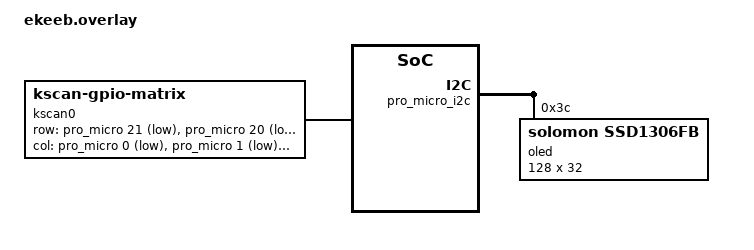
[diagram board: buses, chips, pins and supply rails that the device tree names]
/*
 * Copyright (c) 2021 The ZMK Contributors
 *
 * SPDX-License-Identifier: MIT
 */

/ {
	chosen {
		zephyr,display = &oled;
		zmk,kscan = &kscan0;
	};


	kscan0: kscan_0 {
		compatible = "zmk,kscan-gpio-matrix";

		diode-direction = "col2row";
		row-gpios
			= <&pro_micro 21  (GPIO_ACTIVE_LOW | GPIO_PULL_UP)>
			, <&pro_micro 20  (GPIO_ACTIVE_LOW | GPIO_PULL_UP)>
			, <&pro_micro 19  (GPIO_ACTIVE_LOW | GPIO_PULL_UP)>
			, <&pro_micro 15  (GPIO_ACTIVE_LOW | GPIO_PULL_UP)>
			, <&pro_micro 5   (GPIO_ACTIVE_LOW | GPIO_PULL_UP)>
			, <&pro_micro 6   (GPIO_ACTIVE_LOW | GPIO_PULL_UP)>
			;
		col-gpios
			= <&pro_micro 0  GPIO_ACTIVE_LOW>
			, <&pro_micro 1  GPIO_ACTIVE_LOW>
			, <&pro_micro 4  GPIO_ACTIVE_LOW>
			, <&pro_micro 9  GPIO_ACTIVE_LOW>
			, <&pro_micro 10 GPIO_ACTIVE_LOW>
			, <&pro_micro 14 GPIO_ACTIVE_LOW>
			, <&pro_micro 16 GPIO_ACTIVE_LOW>
			, <&pro_micro 17 GPIO_ACTIVE_LOW>
			, <&pro_micro 18 GPIO_ACTIVE_LOW>
			;
	};

	encoder_1: encoder_1 {
		compatible = "alps,ec11";
		a-gpios = <&pro_micro 7 (GPIO_ACTIVE_HIGH | GPIO_PULL_UP)>;
		b-gpios = <&pro_micro 8 (GPIO_ACTIVE_HIGH | GPIO_PULL_UP)>;
		resolution = <2>;
		status = "disabled";
	};
	
};

&pro_micro_i2c {
	status = "okay";
	oled: ssd1306@3c {
		compatible = "solomon,ssd1306fb";
		reg = <0x3c>;
		width = <128>;
		height = <32>;
		segment-offset = <0>;
		page-offset = <0>;
		display-offset = <0>;
		multiplex-ratio = <31>;
		segment-remap;
		com-invdir;
		com-sequential;
		prechargep = <0x22>;
	};
};
